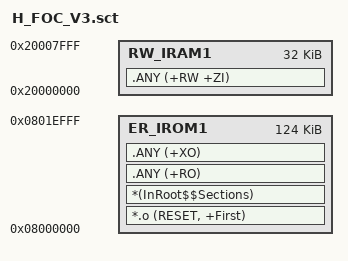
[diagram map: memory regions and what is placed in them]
; *************************************************************
; *** Scatter-Loading Description File generated by uVision ***
; *************************************************************

LR_IROM1 0x08000000 0x0001F000  {    ; last two pages store persistent parameters
  ER_IROM1 0x08000000 0x0001F000  {  ; load address = execution address
   *.o (RESET, +First)
   *(InRoot$$Sections)
   .ANY (+RO)
   .ANY (+XO)
  }
  RW_IRAM1 0x20000000 0x00008000  {  ; RW data
   .ANY (+RW +ZI)
  }
}

